# YTM32B1ME0 register map
Vendor: YTMicro; File version: 1.2
CPU: CM33 r0p4, little endian, MPU, FPU, 2 interrupt priority bits
Registers are 32-bit, read-write, reset 0x0 unless marked. A register's access mark holds for its fields unless they carry their own. Offsets are from the block's base; [hi:lo] are bit positions; {n}, {i} and the like mark numbered series; 'fields as' and 'values as' point back to an identical list.

## CIM — Chip Integration Module
Base 0x4007B000; register names take the prefix CIM_
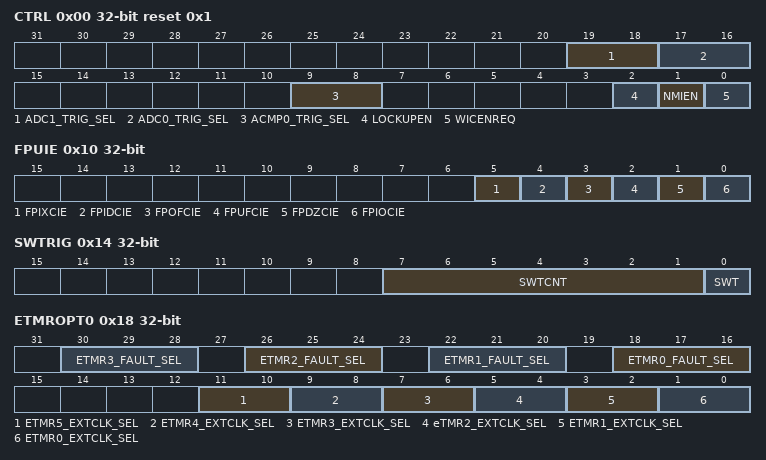
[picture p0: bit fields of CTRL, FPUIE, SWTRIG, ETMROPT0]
0x00 CTRL reset 0x1
  [19:18] ADC1_TRIG_SEL — ADC1 Trigger Select
    0=PTU1 output; 1=TMU output synced by bus clock; 2=TMU output synced by ADC1 func clock
  [17:16] ADC0_TRIG_SEL — ADC0 Trigger Select
    0=PTU0 output; 1=TMU output synced by bus clock; 2=TMU output synced by ADC0 func clock
  [9:8] ACMP0_TRIG_SEL — ACMP0 Trigger Select
    0=TMU; 1=TMU synced by bus clock; 2=TMU synced by ACMP0 func clock
  [2] LOCKUPEN — Enable CPU Lockup Reset
    0=CPU Lockup reset is disabled; 1=CPU Lockup reset is enabled
  [1] NMIEN — Enable NMI function
    0=NMI is disabled; 1=NMI is enabled
  [0] WICENREQ — Enable WIC to wakeup low power mode.
    0=Disable WIC to wakeup low power mode; 1=Enable WIC to wakeup low power mode
0x10 FPUIE
  [all] fields
    0=Disable interrupt; 1=Enable interrupt
  [5] FPIXCIE
  [4] FPIDCIE
  [3] FPOFCIE
  [2] FPUFCIE
  [1] FPDZCIE
  [0] FPIOCIE
0x14 SWTRIG
  [7:1] SWTCNT — Define software trigger valid length (multiplied with bus clock cycle), SWTCNT value will decrease until equal to zero when SWT set.
  [0] SWT — Generate software trigger.
    0=Software trigger is disabled; 1=Generate software trigger and it keeps until SWTCNT equals to zero
0x18 ETMROPT0
  [4n+18:4n+16] ETMR{n}_FAULT_SEL (n=0..3) — Select fault source for eTMR{n}.
    0=eTMR{n} fault 0 input from pad; 1=eTMR{n} fault 0 input from TMU; 0=eTMR{n} fault 1 input from pad; 2=eTMR{n} fault 1 input from TMU; 0=eTMR{n} fault 2 input from pad; 4=eTMR{n} fault 2 input from TMU
  [11:10] ETMR5_EXTCLK_SEL — Select external clock source for eTMR5.
    0=Select TCLK_IN0 input as external clock for eTMR5; 1=Select TCLK_IN1 input as external clock for eTMR5; 2=Select TCLK_IN2 input as external clock for eTMR5
  [9:8] ETMR4_EXTCLK_SEL — Select external clock source for eTMR4.
    0=Select TCLK_IN0 input as external clock for eTMR4; 1=Select TCLK_IN1 input as external clock for eTMR4; 2=Select TCLK_IN2 input as external clock for eTMR4
  [7:6] ETMR3_EXTCLK_SEL — Select external clock source for eTMR3.
    0=Select TCLK_IN0 input as external clock for eTMR3; 1=Select TCLK_IN1 input as external clock for eTMR3; 2=Select TCLK_IN2 input as external clock for eTMR3
  [5:4] eTMR2_EXTCLK_SEL — Select external clock source for eTMR2.
    0=Select TCLK_IN0 input as external clock for eTMR2; 1=Select TCLK_IN1 input as external clock for eTMR2; 2=Select TCLK_IN2 input as external clock for eTMR2
  [3:2] ETMR1_EXTCLK_SEL — Select external clock source for eTMR1.
    0=Select TCLK_IN0 input as external clock for eTMR1; 1=Select TCLK_IN1 input as external clock for eTMR1; 2=Select TCLK_IN2 input as external clock for eTMR1
  [1:0] ETMR0_EXTCLK_SEL — Select external clock source for eTMR0.
    0=Select TCLK_IN0 input as external clock for eTMR0; 1=Select TCLK_IN1 input as external clock for eTMR0; 2=Select TCLK_IN2 input as external clock for eTMR0
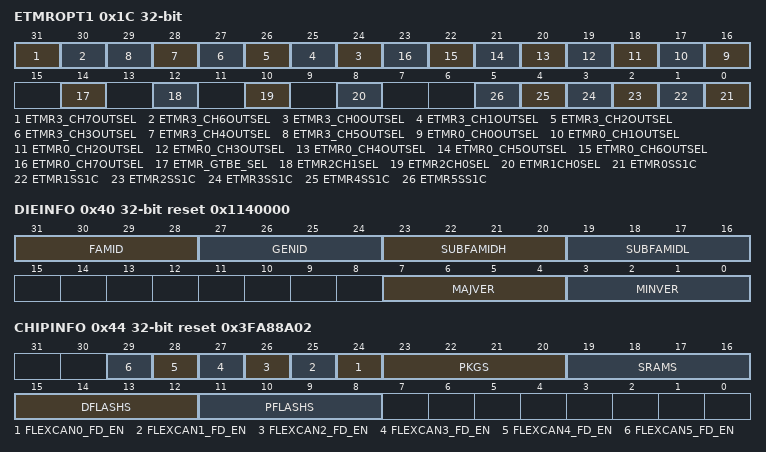
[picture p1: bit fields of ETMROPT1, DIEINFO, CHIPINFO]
0x1C ETMROPT1
  [31] ETMR3_CH7OUTSEL — Select modulation with eTMR2_CH1 for eTMR2 channel 7.
    0=eTMR3 channel 7 output to pad directly; 1=eTMR3 channel 7 output modulation with eTMR2_CH1 output
  [30] ETMR3_CH6OUTSEL — Select modulation with eTMR2_CH1 for eTMR2 channel 6.
    values as ETMR3_CH7OUTSEL
  [n+24] ETMR3_CH{n}OUTSEL (n=0..5) — Select modulation with eTMR2_CH1 for eTMR2 channel {n}.
    0=eTMR3 channel {n} output to pad directly; 1=eTMR3 channel {n} output modulation with eTMR2_CH1 output
  [n+16] ETMR0_CH{n}OUTSEL (n=0..7) — Select modulation with eTMR1_CH1 for eTMR0 channel {n}.
    0=eTMR0 channel {n} output to pad directly; 1=eTMR0 channel {n} output modulation with eTMR1_CH1 output
  [14] ETMR_GTBE_SEL — Split time base enable/disable
    0=All eTMRs have a single global time-base; 1=eTMR0~3 have a common time-base and others have a different common time-base
  [12] ETMR2CH1SEL — Select input source for eTMR2 channel 1.
    0=eTMR2 channel 1 input from pad; 1=eTMR2 channel 1 input from XOR result(eTMR2_CH0, eTMR2_CH1, eTMR1_CH1)
  [10] ETMR2CH0SEL — Select input source for eTMR2 channel 0.
    0=eTMR2 channel 0 input from pad; 1=eTMR2 channel 0 input from ACMP out
  [8] ETMR1CH0SEL — Select input source for eTMR1 channel 0.
    0=eTMR1 channel 0 input from pad; 1=eTMR1 channel 0 input from ACMP out
  [n] ETMR{n}SS1C (n=0..5) — Generate synchronize signal for eTMR{n} trigger 1.
    0=Don't generate synchronize signal for eTMR{n} trigger 1; 1=Generate synchronize signal for eTMR{n} trigger 1
0x40 DIEINFO ro reset 0x1140000
  [31:28] FAMID — Describe the product family information.
    0=B - Basic(General); 1=D - Dashboard; 2=P - Powertrain; 3=V - Vision; 4=N - Networks
  [27:24] GENID — Describe the product generation information.
    1=1st generation production; 2=2nd generation production; 3=3rd generation production
  [23:20] SUBFAMIDH — Describe the product sub family information.
    0=L - Low end; 1=M - Middle end; 2=H - High end
  [19:16] SUBFAMIDL — Describe the product max Flash size information.
    0=A - 64KB; 1=B - 128KB; 2=C - 256KB; 3=D - 512KB; 4=E - 1MB
  [7:4] MAJVER — Describe the major version information.
  [3:0] MINVER — Describe the minor version information.
0x44 CHIPINFO ro reset 0x3FA88A02
  [n+24] FLEXCAN{n}_FD_EN (n=0..5) — FlexCAN{n} FD Feature Enable/Disable
    0=FlexCAN{n} FD Feature is disabled; 1=FlexCAN{n} FD Feature is enabled
  [23:20] PKGS — Describe chip package type information.
    0=16 TSOP; 1=20 TSOP/32 LQFP; 2=32 QFN; 3=48 LQFP; 4=64 LQFP; 8=100 LQFP/MAPBGA; 10=144 LQFP; 12=176 LQFP; 13=257 BGA; 15=289 BGA
  [19:16] SRAMS — Describe sram size information. NOTE: this field indicates TCML or TCMU size (SRAM size divivded by 2).
    2=1KB; 3=2KB; 4=4KB; 5=8KB; 6=16KB; 7=32KB; 8=64KB; 9=128KB; 10=256KB; 11=512KB; 12=1MB; 13=2MB; 14=4MB; 15=8MB
  [15:12] DFLASHS — Describe data flash size information.
    0=1KB; 1=2KB; 2=4KB; 3=8KB; 4=16KB; 5=32KB; 6=64KB; 7=128KB; 8=256KB; 9=512KB
  [11:8] PFLASHS — Describe program flash size information.
    0=1KB; 1=2KB; 2=4KB; 3=8KB; 4=16KB; 5=32KB; 6=64KB; 7=128KB; 8=256KB; 9=512KB; 10=1MB; 11=2MB; 12=4MB; 13=8MB; 14=16MB; 15=32MB
{0x48+4i} UID{i} ro (i=0..3)
  [31:0] UID{i} — Unique identification for the chip.
